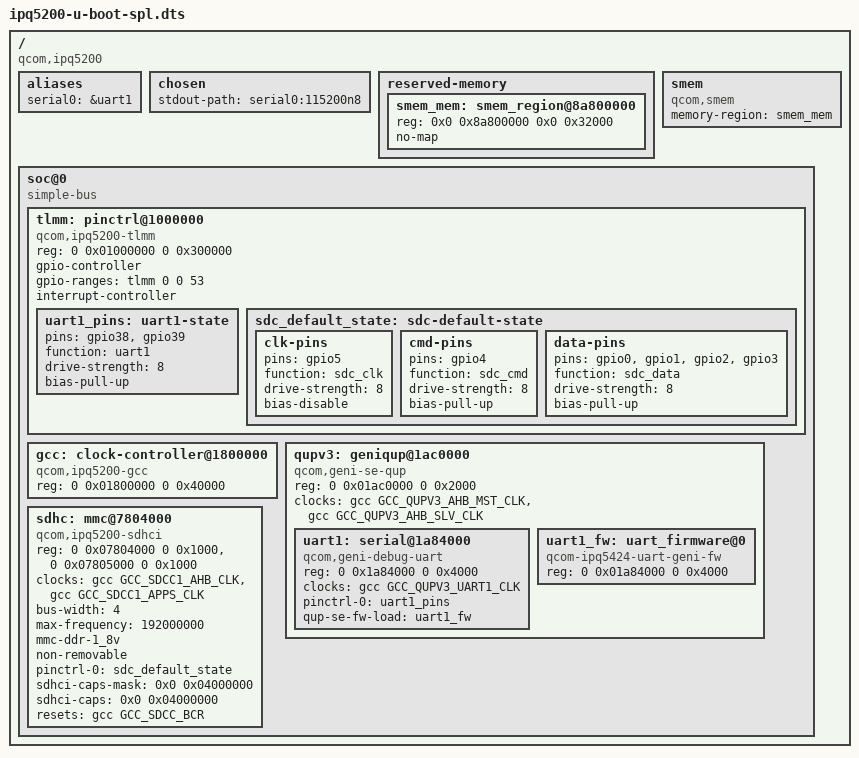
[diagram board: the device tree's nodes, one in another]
// SPDX-License-Identifier: GPL-2.0-only
/*
 * Copyright (c) Qualcomm Technologies, Inc. and/or its subsidiaries.
 */

/dts-v1/;

#include <asm/arch/dt-bindings/clock/qcom,ipq5200-gcc.h>
#include <asm/arch/dt-bindings/reset/qcom,ipq5200-gcc.h>
#include <dt-bindings/gpio/gpio.h>

/ {
	bootph-all;
	compatible = "qcom,ipq5200";

	#address-cells = <2>;
	#size-cells = <2>;

	aliases {
		serial0 = &uart1;
	};

	chosen {
		stdout-path = "serial0:115200n8";
	};

	reserved-memory {
		#address-cells = <2>;
		#size-cells = <2>;
		ranges;

		smem_mem: smem_region@8a800000 {
			bootph-all;
			reg = <0x0 0x8a800000 0x0 0x32000>;
			no-map;
		};
	};

	smem {
		bootph-all;
		compatible = "qcom,smem";
		memory-region = <&smem_mem>;
	};

	soc@0 {
		compatible = "simple-bus";
		#address-cells = <2>;
		#size-cells = <2>;
		ranges = <0 0 0 0 0x10 0>;

		tlmm: pinctrl@1000000 {
			bootph-all;
			compatible = "qcom,ipq5200-tlmm";
			reg = <0 0x01000000 0 0x300000>;
			gpio-controller;
			#gpio-cells = <2>;
			gpio-ranges = <&tlmm 0 0 53>;
			interrupt-controller;
			#interrupt-cells = <2>;

			uart1_pins: uart1-state {
				bootph-all;
				pins = "gpio38", "gpio39";
				function = "uart1";
				drive-strength = <8>;
				bias-pull-up;
			};

			sdc_default_state: sdc-default-state {
				bootph-all;
				clk-pins {
					bootph-all;
					pins = "gpio5";
					function = "sdc_clk";
					drive-strength = <8>;
					bias-disable;
				};

				cmd-pins {
					bootph-all;
					pins = "gpio4";
					function = "sdc_cmd";
					drive-strength = <8>;
					bias-pull-up;
				};

				data-pins {
					bootph-all;
					pins = "gpio0", "gpio1", "gpio2", "gpio3";
					function = "sdc_data";
					drive-strength = <8>;
					bias-pull-up;
				};
			};
		};

		gcc: clock-controller@1800000 {
			bootph-all;
			compatible = "qcom,ipq5200-gcc";
			reg = <0 0x01800000 0 0x40000>;
			#clock-cells = <1>;
			#reset-cells = <1>;
			#power-domain-cells = <1>;
		};

		qupv3: geniqup@1ac0000 {
			bootph-all;
			compatible = "qcom,geni-se-qup";
			reg = <0 0x01ac0000 0 0x2000>;
			clocks = <&gcc GCC_QUPV3_AHB_MST_CLK>,
				 <&gcc GCC_QUPV3_AHB_SLV_CLK>;
			clock-names = "m-ahb", "s-ahb";
			ranges;
			#address-cells = <2>;
			#size-cells = <2>;

			status = "okay";

			uart1: serial@1a84000 {
				bootph-all;
				compatible = "qcom,geni-debug-uart";
				reg = <0 0x1a84000 0 0x4000>;
				clocks = <&gcc GCC_QUPV3_UART1_CLK>;
				clock-names = "se";
				pinctrl-0 = <&uart1_pins>;
				pinctrl-names = "default";
				qup-se-fw-load = <&uart1_fw>;
				status = "okay";
			};

			uart1_fw: uart_firmware@0 {
				bootph-all;
				compatible = "qcom-ipq5424-uart-geni-fw";
				reg = <0 0x01a84000 0 0x4000>;
				status = "okay";
			};
		};

		sdhc: mmc@7804000 {
			bootph-all;
			compatible = "qcom,ipq5200-sdhci", "qcom,sdhci-msm-v5";
			reg = <0 0x07804000 0 0x1000>, <0 0x07805000 0 0x1000>;
			reg-names = "hc", "cqhci";

			clocks = <&gcc GCC_SDCC1_AHB_CLK>,
				 <&gcc GCC_SDCC1_APPS_CLK>;
			clock-names = "iface", "core";

			bus-width = <4>;
			max-frequency = <192000000>;
			mmc-ddr-1_8v;
			non-removable;
			pinctrl-0 = <&sdc_default_state>;
			pinctrl-names = "default";
			sdhci-caps-mask = <0x0 0x04000000>;
			sdhci-caps = <0x0 0x04000000>;
			resets = <&gcc GCC_SDCC_BCR>;
			reset-names = "bcr_rst";
			status = "okay";
		};
	};
};
